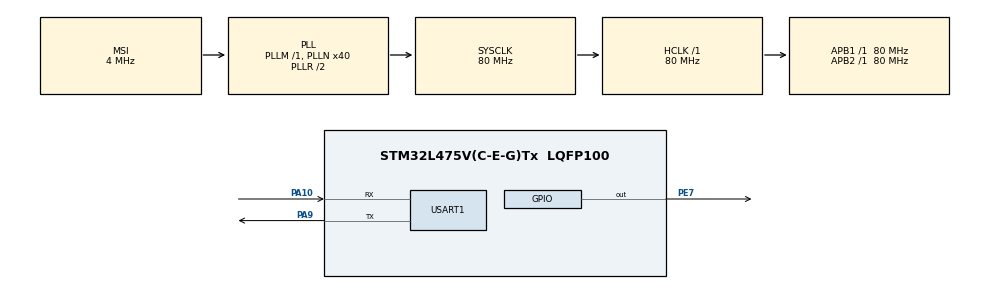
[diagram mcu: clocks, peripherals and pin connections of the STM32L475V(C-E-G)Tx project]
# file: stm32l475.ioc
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Mcu.Family=STM32L4
Mcu.Name=STM32L475V(C-E-G)Tx
Mcu.Package=LQFP100
NVIC.PriorityGroup=NVIC_PRIORITYGROUP_4
PA10.Mode=Asynchronous
PA10.Signal=USART1_RX
PA13\ (JTMS-SWDIO).Mode=Serial_Wire
PA13\ (JTMS-SWDIO).Signal=SYS_JTMS-SWDIO
PA14\ (JTCK-SWCLK).Mode=Serial_Wire
PA14\ (JTCK-SWCLK).Signal=SYS_JTCK-SWCLK
PA9.Mode=Asynchronous
PA9.Signal=USART1_TX
PE7.Signal=GPIO_Output
ProjectManager.HeapSize=0x200
ProjectManager.StackSize=0x400
ProjectManager.TargetToolchain=STM32CubeIDE
RCC.AHBFreq_Value=80000000
RCC.APB1Freq_Value=80000000
RCC.APB1TimFreq_Value=80000000
RCC.APB2Freq_Value=80000000
RCC.APB2TimFreq_Value=80000000
RCC.CortexFreq_Value=80000000
RCC.HCLKFreq_Value=80000000
RCC.HSE_VALUE=8000000
RCC.HSI_VALUE=16000000
RCC.LSE_VALUE=32768
RCC.MSI_VALUE=4000000
RCC.PLLN=40
RCC.SYSCLKFreq_VALUE=80000000
RCC.SYSCLKSource=RCC_SYSCLKSOURCE_PLLCLK
RCC.VCOOutputFreq_Value=160000000
USART1.VirtualMode-Asynchronous=VM_ASYNC
board=custom

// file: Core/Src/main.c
/* USER CODE BEGIN Header */
/**
  ******************************************************************************
  * @file           : main.c
  * @brief          : Main program body
  ******************************************************************************
  * @attention
  *
  * <h2><center>&copy; Copyright (c) 2020 STMicroelectronics.
  * All rights reserved.</center></h2>
  *
  * This software component is licensed by ST under BSD 3-Clause license,
  * the "License"; You may not use this file except in compliance with the
  * License. You may obtain a copy of the License at:
  *                        opensource.org/licenses/BSD-3-Clause
  *
  ******************************************************************************
  */
/* USER CODE END Header */

#include "main.h"

UART_HandleTypeDef huart1;

/* USER CODE BEGIN PV */

/* USER CODE BEGIN 1 */

/* USER CODE END 1 */

/* USER CODE END PV */

void SystemClock_Config(void);
static void MX_GPIO_Init(void);
static void MX_USART1_UART_Init(void);

/* USER CODE BEGIN 0 */
#include "tx_api.h"
char debug_buf[128];

TX_THREAD               		led_thread;
TX_THREAD               		printf_thread;
#define DEMO_STACK_SIZE         4096
static uint8_t led_thread_stack[DEMO_STACK_SIZE];
static uint8_t printf_thread_stack[DEMO_STACK_SIZE];

void led_thread_entry(ULONG thread_input)
{
    /* This thread simply sits in while-forever-sleep loop.  */
    while(1)
    {
		HAL_GPIO_WritePin(GPIOE, GPIO_PIN_7, GPIO_PIN_RESET);
		tx_thread_sleep(1000);
		HAL_GPIO_WritePin(GPIOE, GPIO_PIN_7, GPIO_PIN_SET);
		tx_thread_sleep(1000);
    }
}

void printf_thread_entry(ULONG thread_input)
{
    while(1)
    {
    	debug("hello tyustli\r\n");
    	tx_thread_sleep(1000);
    }
}
void tx_application_define(void *first_unused_memory)
{
    /* Create the led thread.  */
    tx_thread_create(&led_thread,
					 "led thread",
					 led_thread_entry,
					 0,
					 led_thread_stack,
					 DEMO_STACK_SIZE,
					 1,
					 1,
					 TX_NO_TIME_SLICE,
					 TX_AUTO_START);

    /* Create the printf thread.  */
    tx_thread_create(&printf_thread,
					 "printf thread",
					 printf_thread_entry,
					 0,
					 printf_thread_stack,
					 DEMO_STACK_SIZE,
					 2,
					 2,
					 TX_NO_TIME_SLICE,
					 TX_AUTO_START);
}
/* USER CODE END 0 */

int main(void)
{

  /* MCU Configuration--------------------------------------------------------*/

  /* Reset of all peripherals, Initializes the Flash interface and the Systick. */
  HAL_Init();

  /* Configure the system clock */
  SystemClock_Config();

  /* Initialize all configured peripherals */
  MX_GPIO_Init();
  MX_USART1_UART_Init();
  /* USER CODE BEGIN 2 */
  tx_kernel_enter();

  /* USER CODE END 2 */

  /* Infinite loop */
  while (1)
  {

  }
}

void SystemClock_Config(void)
{
  RCC_OscInitTypeDef RCC_OscInitStruct = {0};
  RCC_ClkInitTypeDef RCC_ClkInitStruct = {0};
  RCC_PeriphCLKInitTypeDef PeriphClkInit = {0};

  /** Initializes the CPU, AHB and APB busses clocks
  */
  RCC_OscInitStruct.OscillatorType = RCC_OSCILLATORTYPE_MSI;
  RCC_OscInitStruct.MSIState = RCC_MSI_ON;
  RCC_OscInitStruct.MSICalibrationValue = 0;
  RCC_OscInitStruct.MSIClockRange = RCC_MSIRANGE_6;
  RCC_OscInitStruct.PLL.PLLState = RCC_PLL_ON;
  RCC_OscInitStruct.PLL.PLLSource = RCC_PLLSOURCE_MSI;
  RCC_OscInitStruct.PLL.PLLM = 1;
  RCC_OscInitStruct.PLL.PLLN = 40;
  RCC_OscInitStruct.PLL.PLLP = RCC_PLLP_DIV7;
  RCC_OscInitStruct.PLL.PLLQ = RCC_PLLQ_DIV2;
  RCC_OscInitStruct.PLL.PLLR = RCC_PLLR_DIV2;
  if (HAL_RCC_OscConfig(&RCC_OscInitStruct) != HAL_OK)
  {
    Error_Handler();
  }
  /** Initializes the CPU, AHB and APB busses clocks
  */
  RCC_ClkInitStruct.ClockType = RCC_CLOCKTYPE_HCLK|RCC_CLOCKTYPE_SYSCLK
                              |RCC_CLOCKTYPE_PCLK1|RCC_CLOCKTYPE_PCLK2;
  RCC_ClkInitStruct.SYSCLKSource = RCC_SYSCLKSOURCE_PLLCLK;
  RCC_ClkInitStruct.AHBCLKDivider = RCC_SYSCLK_DIV1;
  RCC_ClkInitStruct.APB1CLKDivider = RCC_HCLK_DIV1;
  RCC_ClkInitStruct.APB2CLKDivider = RCC_HCLK_DIV1;

  if (HAL_RCC_ClockConfig(&RCC_ClkInitStruct, FLASH_LATENCY_4) != HAL_OK)
  {
    Error_Handler();
  }
  PeriphClkInit.PeriphClockSelection = RCC_PERIPHCLK_USART1;
  PeriphClkInit.Usart1ClockSelection = RCC_USART1CLKSOURCE_PCLK2;
  if (HAL_RCCEx_PeriphCLKConfig(&PeriphClkInit) != HAL_OK)
  {
    Error_Handler();
  }
  /** Configure the main internal regulator output voltage
  */
  if (HAL_PWREx_ControlVoltageScaling(PWR_REGULATOR_VOLTAGE_SCALE1) != HAL_OK)
  {
    Error_Handler();
  }
}

static void MX_USART1_UART_Init(void)
{

  huart1.Instance = USART1;
  huart1.Init.BaudRate = 115200;
  huart1.Init.WordLength = UART_WORDLENGTH_8B;
  huart1.Init.StopBits = UART_STOPBITS_1;
  huart1.Init.Parity = UART_PARITY_NONE;
  huart1.Init.Mode = UART_MODE_TX_RX;
  huart1.Init.HwFlowCtl = UART_HWCONTROL_NONE;
  huart1.Init.OverSampling = UART_OVERSAMPLING_16;
  huart1.Init.OneBitSampling = UART_ONE_BIT_SAMPLE_DISABLE;
  huart1.AdvancedInit.AdvFeatureInit = UART_ADVFEATURE_NO_INIT;
  if (HAL_UART_Init(&huart1) != HAL_OK)
  {
    Error_Handler();
  }

}

static void MX_GPIO_Init(void)
{
  GPIO_InitTypeDef GPIO_InitStruct = {0};

  /* GPIO Ports Clock Enable */
  __HAL_RCC_GPIOE_CLK_ENABLE();
  __HAL_RCC_GPIOA_CLK_ENABLE();

  /*Configure GPIO pin Output Level */
  HAL_GPIO_WritePin(GPIOE, GPIO_PIN_7, GPIO_PIN_RESET);

  /*Configure GPIO pin : PE7 */
  GPIO_InitStruct.Pin = GPIO_PIN_7;
  GPIO_InitStruct.Mode = GPIO_MODE_OUTPUT_PP;
  GPIO_InitStruct.Pull = GPIO_NOPULL;
  GPIO_InitStruct.Speed = GPIO_SPEED_FREQ_LOW;
  HAL_GPIO_Init(GPIOE, &GPIO_InitStruct);

}

void Error_Handler(void)
{
}

/************************ (C) COPYRIGHT STMicroelectronics *****END OF FILE****/
